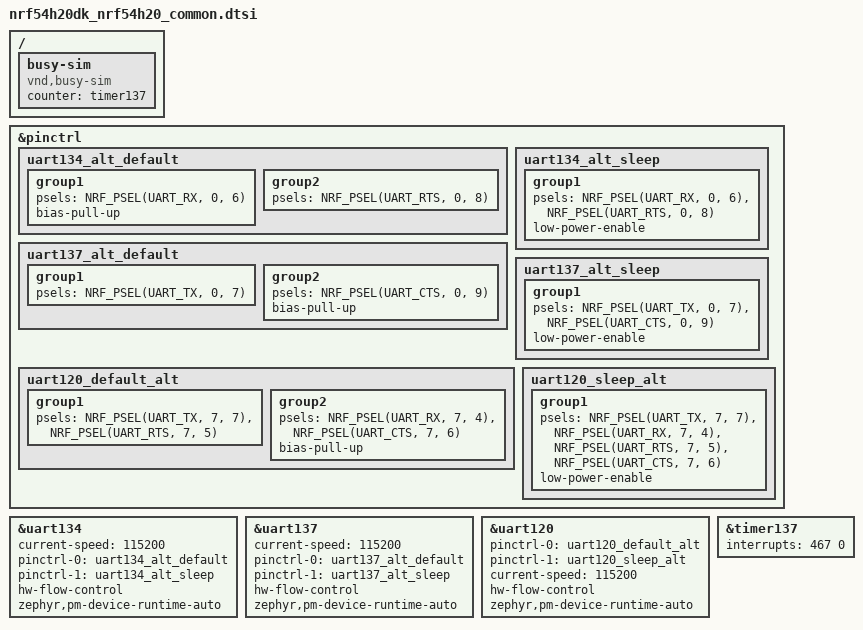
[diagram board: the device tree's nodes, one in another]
/* SPDX-License-Identifier: Apache-2.0 */

&pinctrl {
	uart134_alt_default: uart134_alt_default {
		group1 {
			psels = <NRF_PSEL(UART_RX, 0, 6)>;
			bias-pull-up;
		};
		group2 {
			psels = <NRF_PSEL(UART_RTS, 0, 8)>;
		};
	};

	uart134_alt_sleep: uart134_alt_sleep {
		group1 {
			psels = <NRF_PSEL(UART_RX, 0, 6)>,
				<NRF_PSEL(UART_RTS, 0, 8)>;
			low-power-enable;
		};
	};

	uart137_alt_default: uart137_alt_default {
		group1 {
			psels = <NRF_PSEL(UART_TX, 0, 7)>;
		};
		group2 {
			psels = <NRF_PSEL(UART_CTS, 0, 9)>;
			bias-pull-up;
		};
	};

	uart137_alt_sleep: uart137_alt_sleep {
		group1 {
			psels = <NRF_PSEL(UART_TX, 0, 7)>,
				<NRF_PSEL(UART_CTS, 0, 9)>;
			low-power-enable;
		};
	};

	uart120_default_alt: uart120_default_alt {
		group1 {
			psels = <NRF_PSEL(UART_TX, 7, 7)>,
				<NRF_PSEL(UART_RTS, 7, 5)>;
		};
		group2 {
			psels = <NRF_PSEL(UART_RX, 7, 4)>,
				<NRF_PSEL(UART_CTS, 7, 6)>;
			bias-pull-up;
		};
	};

	uart120_sleep_alt: uart120_sleep_alt {
		group1 {
			psels = <NRF_PSEL(UART_TX, 7, 7)>,
				<NRF_PSEL(UART_RX, 7, 4)>,
				<NRF_PSEL(UART_RTS, 7, 5)>,
				<NRF_PSEL(UART_CTS, 7, 6)>;
			low-power-enable;
		};
	};
};

dut: &uart134 {
	status = "okay";
	current-speed = <115200>;
	pinctrl-0 = <&uart134_alt_default>;
	pinctrl-1 = <&uart134_alt_sleep>;
	pinctrl-names = "default", "sleep";
	hw-flow-control;
	zephyr,pm-device-runtime-auto;
};

dut_aux: &uart137 {
	status = "okay";
	current-speed = <115200>;
	pinctrl-0 = <&uart137_alt_default>;
	pinctrl-1 = <&uart137_alt_sleep>;
	pinctrl-names = "default", "sleep";
	hw-flow-control;
	zephyr,pm-device-runtime-auto;
};

dut2: &uart120 {
	pinctrl-0 = <&uart120_default_alt>;
	pinctrl-1 = <&uart120_sleep_alt>;
	pinctrl-names = "default", "sleep";
	current-speed = <115200>;
	hw-flow-control;
	zephyr,pm-device-runtime-auto;
};

&timer137 {
	status = "okay";
	interrupts = <467 0>;
};

/ {
	busy-sim {
		compatible = "vnd,busy-sim";
		status = "okay";
		counter = <&timer137>;
	};
};
